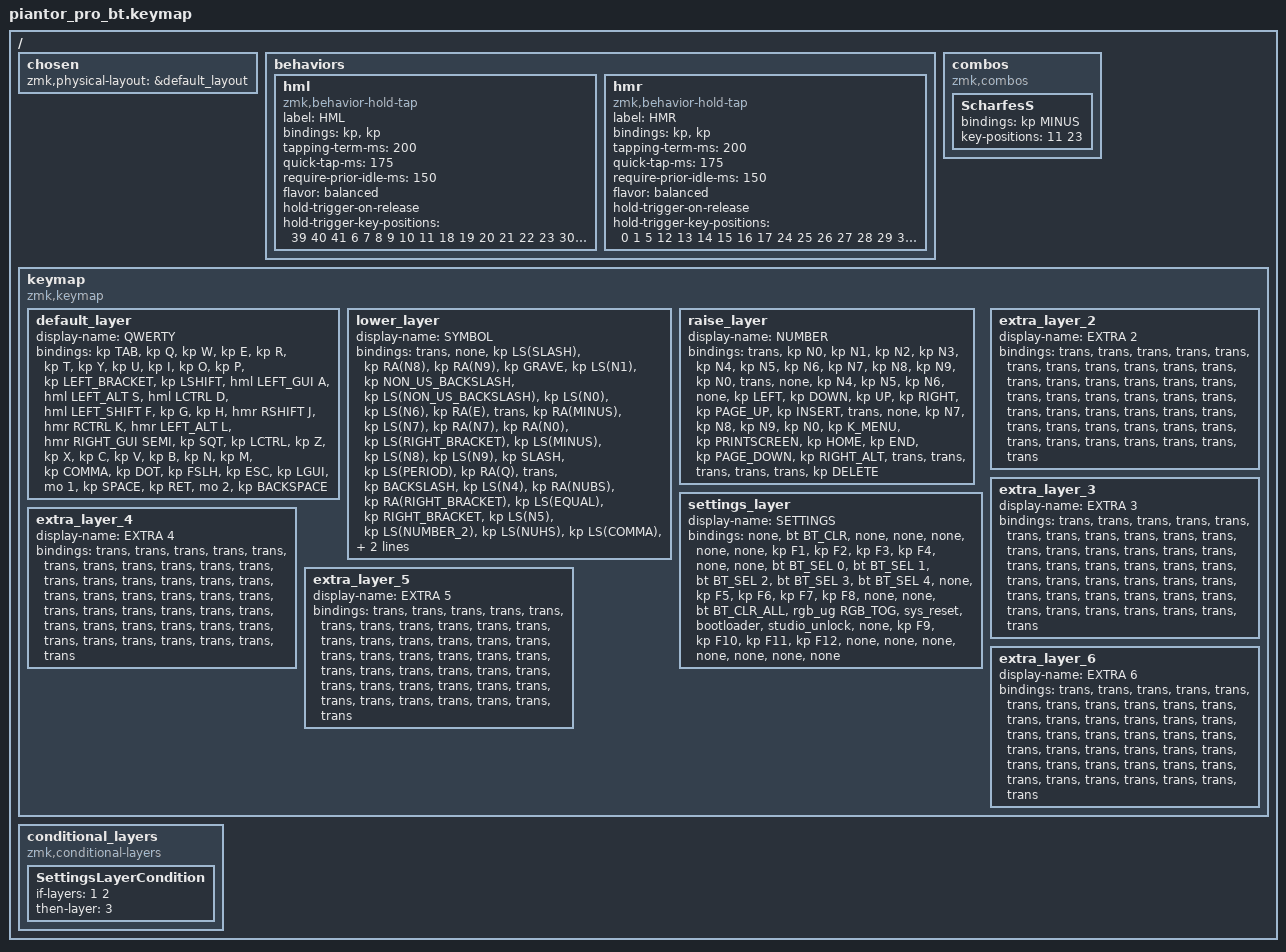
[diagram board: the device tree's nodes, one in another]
/*
 * Copyright (c) 2020 The ZMK Contributors
 *
 * SPDX-License-Identifier: MIT
 */

#include <behaviors.dtsi>
#include <dt-bindings/zmk/bt.h>
#include <dt-bindings/zmk/keys.h>
#include <dt-bindings/zmk/rgb.h>

/ {
    chosen { zmk,physical-layout = &default_layout; };
};

/ {
    behaviors {
        hml: hml {
            compatible = "zmk,behavior-hold-tap";
            label = "HML";
            bindings = <&kp>, <&kp>;

            #binding-cells = <2>;
            tapping-term-ms = <200>;
            quick-tap-ms = <175>;
            require-prior-idle-ms = <150>;
            flavor = "balanced";
            hold-trigger-on-release;
            hold-trigger-key-positions = <39 40 41 6 7 8 9 10 11 18 19 20 21 22 23 30 31 32 33 34 35 40 41 38 37 36>;
        };

        hmr: hmr {
            compatible = "zmk,behavior-hold-tap";
            label = "HMR";
            bindings = <&kp>, <&kp>;

            #binding-cells = <2>;
            tapping-term-ms = <200>;
            quick-tap-ms = <175>;
            require-prior-idle-ms = <150>;
            flavor = "balanced";
            hold-trigger-on-release;
            hold-trigger-key-positions = <0 1 5 12 13 14 15 16 17 24 25 26 27 28 29 36 37 38 2 3 4 39 40 41>;
        };
    };

    combos {
        compatible = "zmk,combos";

        ScharfesS {
            bindings = <&kp MINUS>;
            key-positions = <11 23>;
        };
    };

    keymap {
        compatible = "zmk,keymap";

        default_layer {
            display-name = "QWERTY";

            // --------------------------------------------------------------------------------
            // |  TAB |  Q  |  W  |  E  |  R  |  T  |  Y  |  U   |  I  |  O  |  P  | BSPC |
            // | CTRL |  A  |  S  |  D  |  F  |  G  |  H  |  J   |  K  |  L  |  ;  |  '   |
            // | SHFT |  Z  |  X  |  C  |  V  |  B  |  N  |  M   |  ,  |  .  |  /  | ESC  |
            //                    | GUI | LWR | SPC | ENT | RSE  | ALT |

            bindings = <
&kp TAB  &kp Q  &kp W  &kp E  &kp R  &kp T  &kp Y  &kp U  &kp I  &kp O  &kp P  &kp LEFT_BRACKET  &kp LSHIFT  &hml LEFT_GUI A  &hml LEFT_ALT S  &hml LCTRL D  &hml LEFT_SHIFT F  &kp G  &kp H  &hmr RSHIFT J  &hmr RCTRL K  &hmr LEFT_ALT L  &hmr RIGHT_GUI SEMI  &kp SQT  &kp LCTRL  &kp Z  &kp X  &kp C  &kp V  &kp B  &kp N  &kp M  &kp COMMA  &kp DOT  &kp FSLH  &kp ESC  &kp LGUI  &mo 1  &kp SPACE  &kp RET  &mo 2  &kp BACKSPACE
            >;
        };

        lower_layer {
            display-name = "SYMBOL";

            // -----------------------------------------------------------------------------------------
            // |  TAB |  !  |  @  |  #  |  $  |  %  |  ^  |  &  |  *  |  (  |  )  | BSPC |
            // | CTRL |     |     |     |     |     |  -  |  =  |  [  |  ]  |  \  |  `   |
            // | SHFT |     |     |     |     |     |  _  |  +  |  {  |  }  | "|" |  ~   |
            //                    | GUI |     | SPC | ENT |     | ALT |

            bindings = <
&trans  &none  &kp LS(SLASH)  &kp RA(N8)  &kp RA(N9)  &kp GRAVE  &kp LS(N1)  &kp NON_US_BACKSLASH  &kp LS(NON_US_BACKSLASH)  &kp LS(N0)  &kp LS(N6)  &kp RA(E)  &trans  &kp RA(MINUS)  &kp LS(N7)  &kp RA(N7)  &kp RA(N0)  &kp LS(RIGHT_BRACKET)  &kp LS(MINUS)  &kp LS(N8)  &kp LS(N9)  &kp SLASH  &kp LS(PERIOD)  &kp RA(Q)  &trans  &kp BACKSLASH  &kp LS(N4)  &kp RA(NUBS)  &kp RA(RIGHT_BRACKET)  &kp LS(EQUAL)  &kp RIGHT_BRACKET  &kp LS(N5)  &kp LS(NUMBER_2)  &kp LS(NUHS)  &kp LS(COMMA)  &none  &trans  &trans  &trans  &trans  &trans  &trans
            >;
        };

        raise_layer {
            display-name = "NUMBER";

            // -----------------------------------------------------------------------------------------
            // |  TAB |  1  |  2  |  3  |  4  |  5    |  6  |  7  |  8  |  9  |  0  | BSPC |
            // | CTRL | BT1 | BT2 | BT3 | BT4 | BT5   | LFT | DWN |  UP | RGT |     |      |
            // | SHFT | BTCR| RGB | RST | BOOT| Unlock|     |     |     |     |     |      |
            //                    | GUI |     | SPC   | ENT |     | ALT |

            bindings = <
&trans  &kp N0  &kp N1  &kp N2  &kp N3  &kp N4  &kp N5  &kp N6  &kp N7  &kp N8  &kp N9  &kp N0  &trans  &none  &kp N4  &kp N5  &kp N6  &none  &kp LEFT  &kp DOWN  &kp UP  &kp RIGHT  &kp PAGE_UP  &kp INSERT  &trans  &none  &kp N7  &kp N8  &kp N9  &kp N0  &kp K_MENU  &kp PRINTSCREEN  &kp HOME  &kp END  &kp PAGE_DOWN  &kp RIGHT_ALT  &trans  &trans  &trans  &trans  &trans  &kp DELETE
            >;
        };

        settings_layer {
            display-name = "SETTINGS";
            bindings = <
&none  &bt BT_CLR  &none  &none  &none  &none  &none  &kp F1  &kp F2  &kp F3  &kp F4  &none  &none  &bt BT_SEL 0  &bt BT_SEL 1  &bt BT_SEL 2  &bt BT_SEL 3  &bt BT_SEL 4  &none  &kp F5  &kp F6  &kp F7  &kp F8  &none  &none  &bt BT_CLR_ALL  &rgb_ug RGB_TOG  &sys_reset  &bootloader  &studio_unlock  &none  &kp F9  &kp F10  &kp F11  &kp F12  &none  &none  &none  &none  &none  &none  &none
            >;
        };

        extra_layer_2 {
            display-name = "EXTRA 2";
            bindings = <
&trans  &trans  &trans  &trans  &trans  &trans  &trans  &trans  &trans  &trans  &trans  &trans  &trans  &trans  &trans  &trans  &trans  &trans  &trans  &trans  &trans  &trans  &trans  &trans  &trans  &trans  &trans  &trans  &trans  &trans  &trans  &trans  &trans  &trans  &trans  &trans  &trans  &trans  &trans  &trans  &trans  &trans
            >;
        };

        extra_layer_3 {
            display-name = "EXTRA 3";
            bindings = <
&trans  &trans  &trans  &trans  &trans  &trans  &trans  &trans  &trans  &trans  &trans  &trans  &trans  &trans  &trans  &trans  &trans  &trans  &trans  &trans  &trans  &trans  &trans  &trans  &trans  &trans  &trans  &trans  &trans  &trans  &trans  &trans  &trans  &trans  &trans  &trans  &trans  &trans  &trans  &trans  &trans  &trans
            >;
        };

        extra_layer_4 {
            display-name = "EXTRA 4";
            bindings = <
&trans  &trans  &trans  &trans  &trans  &trans  &trans  &trans  &trans  &trans  &trans  &trans  &trans  &trans  &trans  &trans  &trans  &trans  &trans  &trans  &trans  &trans  &trans  &trans  &trans  &trans  &trans  &trans  &trans  &trans  &trans  &trans  &trans  &trans  &trans  &trans  &trans  &trans  &trans  &trans  &trans  &trans
            >;
        };

        extra_layer_5 {
            display-name = "EXTRA 5";
            bindings = <
&trans  &trans  &trans  &trans  &trans  &trans  &trans  &trans  &trans  &trans  &trans  &trans  &trans  &trans  &trans  &trans  &trans  &trans  &trans  &trans  &trans  &trans  &trans  &trans  &trans  &trans  &trans  &trans  &trans  &trans  &trans  &trans  &trans  &trans  &trans  &trans  &trans  &trans  &trans  &trans  &trans  &trans
            >;
        };

        extra_layer_6 {
            display-name = "EXTRA 6";
            bindings = <
&trans  &trans  &trans  &trans  &trans  &trans  &trans  &trans  &trans  &trans  &trans  &trans  &trans  &trans  &trans  &trans  &trans  &trans  &trans  &trans  &trans  &trans  &trans  &trans  &trans  &trans  &trans  &trans  &trans  &trans  &trans  &trans  &trans  &trans  &trans  &trans  &trans  &trans  &trans  &trans  &trans  &trans
            >;
        };
    };

    conditional_layers {
        compatible = "zmk,conditional-layers";

        SettingsLayerCondition {
            if-layers = <1 2>;
            then-layer = <3>;
        };
    };
};
